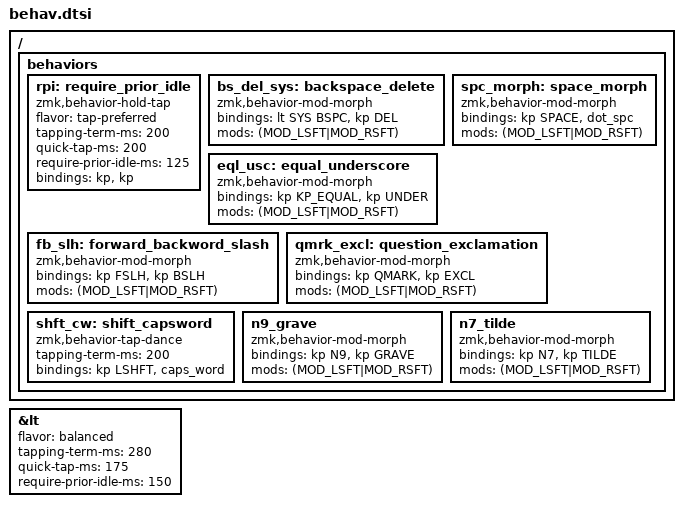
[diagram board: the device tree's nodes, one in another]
&lt {
  flavor = "balanced";
  tapping-term-ms = <280>;
  quick-tap-ms = <175>;
  require-prior-idle-ms = <150>;
};

/ {
  behaviors {
    rpi: require_prior_idle {
        compatible = "zmk,behavior-hold-tap";
        #binding-cells = <2>;
        flavor = "tap-preferred";
        tapping-term-ms = <200>;
        quick-tap-ms = <200>;
        require-prior-idle-ms = <125>;
        bindings = <&kp>, <&kp>;
    };

    // tap: backspace | shift+tap: delete | hold: SYS layer 
    bs_del_sys: backspace_delete {
      compatible = "zmk,behavior-mod-morph";
      #binding-cells = <0>;
      bindings = <&lt SYS BSPC>, <&kp DEL>;
      mods = <(MOD_LSFT|MOD_RSFT)>;
    };

    spc_morph: space_morph {
      compatible = "zmk,behavior-mod-morph";
      #binding-cells = <0>;
      bindings = <&kp SPACE>, <&dot_spc>;
      mods = <(MOD_LSFT|MOD_RSFT)>;
    };

    eql_usc: equal_underscore {
      compatible = "zmk,behavior-mod-morph";
      #binding-cells = <0>;
      bindings = <&kp KP_EQUAL>, <&kp UNDER>;
      mods = <(MOD_LSFT|MOD_RSFT)>;
    };

    fb_slh: forward_backword_slash {
      compatible = "zmk,behavior-mod-morph";
      #binding-cells = <0>;
      bindings = <&kp FSLH>, <&kp BSLH>;
      mods = <(MOD_LSFT|MOD_RSFT)>;
    };

    qmrk_excl: question_exclamation {
      compatible = "zmk,behavior-mod-morph";
      #binding-cells = <0>;
      bindings = <&kp QMARK>, <&kp EXCL>;
      mods = <(MOD_LSFT|MOD_RSFT)>;
    };

    shft_cw: shift_capsword {
      compatible = "zmk,behavior-tap-dance";
      #binding-cells = <0>;
      tapping-term-ms = <200>;
      bindings = <&kp LSHFT>, <&caps_word>;
    };

    n9_grave: n9_grave {
      compatible = "zmk,behavior-mod-morph";
      #binding-cells = <0>;
      bindings = <&kp N9>, <&kp GRAVE>;
      mods = <(MOD_LSFT|MOD_RSFT)>;
    };

    n7_tilde: n7_tilde {
      compatible = "zmk,behavior-mod-morph";
      #binding-cells = <0>;
      bindings = <&kp N7>, <&kp TILDE>;
      mods = <(MOD_LSFT|MOD_RSFT)>;
    };
  };
};

